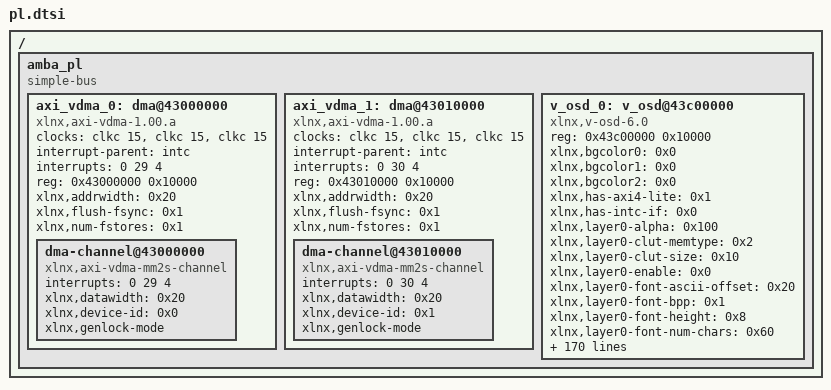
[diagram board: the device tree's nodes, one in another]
/*
 * CAUTION: This file is automatically generated by Xilinx.
 * Version: HSI 2016.3
 * Today is: Tue Nov 29 15:11:29 2016
*/


/ {
	amba_pl: amba_pl {
		#address-cells = <1>;
		#size-cells = <1>;
		compatible = "simple-bus";
		ranges ;
		axi_vdma_0: dma@43000000 {
			#dma-cells = <1>;
			clock-names = "s_axi_lite_aclk", "m_axi_mm2s_aclk", "m_axi_mm2s_aclk";
			clocks = <&clkc 15>, <&clkc 15>, <&clkc 15>;
			compatible = "xlnx,axi-vdma-1.00.a";
			interrupt-parent = <&intc>;
			interrupts = <0 29 4>;
			reg = <0x43000000 0x10000>;
			xlnx,addrwidth = <0x20>;
			xlnx,flush-fsync = <0x1>;
			xlnx,num-fstores = <0x1>;
			dma-channel@43000000 {
				compatible = "xlnx,axi-vdma-mm2s-channel";
				interrupts = <0 29 4>;
				xlnx,datawidth = <0x20>;
				xlnx,device-id = <0x0>;
				xlnx,genlock-mode ;
			};
		};
		axi_vdma_1: dma@43010000 {
			#dma-cells = <1>;
			clock-names = "s_axi_lite_aclk", "m_axi_mm2s_aclk", "m_axi_mm2s_aclk";
			clocks = <&clkc 15>, <&clkc 15>, <&clkc 15>;
			compatible = "xlnx,axi-vdma-1.00.a";
			interrupt-parent = <&intc>;
			interrupts = <0 30 4>;
			reg = <0x43010000 0x10000>;
			xlnx,addrwidth = <0x20>;
			xlnx,flush-fsync = <0x1>;
			xlnx,num-fstores = <0x1>;
			dma-channel@43010000 {
				compatible = "xlnx,axi-vdma-mm2s-channel";
				interrupts = <0 30 4>;
				xlnx,datawidth = <0x20>;
				xlnx,device-id = <0x1>;
				xlnx,genlock-mode ;
			};
		};
		v_osd_0: v_osd@43c00000 {
			compatible = "xlnx,v-osd-6.0";
			reg = <0x43c00000 0x10000>;
			xlnx,bgcolor0 = <0x0>;
			xlnx,bgcolor1 = <0x0>;
			xlnx,bgcolor2 = <0x0>;
			xlnx,has-axi4-lite = <0x1>;
			xlnx,has-intc-if = <0x0>;
			xlnx,layer0-alpha = <0x100>;
			xlnx,layer0-clut-memtype = <0x2>;
			xlnx,layer0-clut-size = <0x10>;
			xlnx,layer0-enable = <0x0>;
			xlnx,layer0-font-ascii-offset = <0x20>;
			xlnx,layer0-font-bpp = <0x1>;
			xlnx,layer0-font-height = <0x8>;
			xlnx,layer0-font-num-chars = <0x60>;
			xlnx,layer0-font-width = <0x8>;
			xlnx,layer0-galpha-en = <0x1>;
			xlnx,layer0-imem-size = <0x30>;
			xlnx,layer0-ins-box-en = <0x1>;
			xlnx,layer0-ins-line-en = <0x0>;
			xlnx,layer0-ins-text-en = <0x1>;
			xlnx,layer0-priority = <0x0>;
			xlnx,layer0-text-max-string-length = <0x20>;
			xlnx,layer0-text-num-strings = <0x8>;
			xlnx,layer0-type = <0x2>;
			xlnx,layer0-x-pos = <0x0>;
			xlnx,layer0-x-size = <0x140>;
			xlnx,layer0-y-pos = <0x0>;
			xlnx,layer0-y-size = <0xf0>;
			xlnx,layer1-alpha = <0x100>;
			xlnx,layer1-clut-memtype = <0x2>;
			xlnx,layer1-clut-size = <0x10>;
			xlnx,layer1-enable = <0x0>;
			xlnx,layer1-font-ascii-offset = <0x20>;
			xlnx,layer1-font-bpp = <0x1>;
			xlnx,layer1-font-height = <0x8>;
			xlnx,layer1-font-num-chars = <0x60>;
			xlnx,layer1-font-width = <0x8>;
			xlnx,layer1-galpha-en = <0x1>;
			xlnx,layer1-imem-size = <0x30>;
			xlnx,layer1-ins-box-en = <0x1>;
			xlnx,layer1-ins-line-en = <0x0>;
			xlnx,layer1-ins-text-en = <0x1>;
			xlnx,layer1-priority = <0x1>;
			xlnx,layer1-text-max-string-length = <0x20>;
			xlnx,layer1-text-num-strings = <0x8>;
			xlnx,layer1-type = <0x2>;
			xlnx,layer1-x-pos = <0x0>;
			xlnx,layer1-x-size = <0x140>;
			xlnx,layer1-y-pos = <0x0>;
			xlnx,layer1-y-size = <0xf0>;
			xlnx,layer2-alpha = <0x100>;
			xlnx,layer2-clut-memtype = <0x2>;
			xlnx,layer2-clut-size = <0x10>;
			xlnx,layer2-enable = <0x0>;
			xlnx,layer2-font-ascii-offset = <0x20>;
			xlnx,layer2-font-bpp = <0x1>;
			xlnx,layer2-font-height = <0x8>;
			xlnx,layer2-font-num-chars = <0x60>;
			xlnx,layer2-font-width = <0x8>;
			xlnx,layer2-galpha-en = <0x1>;
			xlnx,layer2-imem-size = <0x30>;
			xlnx,layer2-ins-box-en = <0x1>;
			xlnx,layer2-ins-line-en = <0x0>;
			xlnx,layer2-ins-text-en = <0x1>;
			xlnx,layer2-priority = <0x2>;
			xlnx,layer2-text-max-string-length = <0x20>;
			xlnx,layer2-text-num-strings = <0x8>;
			xlnx,layer2-type = <0x2>;
			xlnx,layer2-x-pos = <0x0>;
			xlnx,layer2-x-size = <0x140>;
			xlnx,layer2-y-pos = <0x0>;
			xlnx,layer2-y-size = <0xf0>;
			xlnx,layer3-alpha = <0x100>;
			xlnx,layer3-clut-memtype = <0x2>;
			xlnx,layer3-clut-size = <0x10>;
			xlnx,layer3-enable = <0x0>;
			xlnx,layer3-font-ascii-offset = <0x20>;
			xlnx,layer3-font-bpp = <0x1>;
			xlnx,layer3-font-height = <0x8>;
			xlnx,layer3-font-num-chars = <0x60>;
			xlnx,layer3-font-width = <0x8>;
			xlnx,layer3-galpha-en = <0x1>;
			xlnx,layer3-imem-size = <0x30>;
			xlnx,layer3-ins-box-en = <0x1>;
			xlnx,layer3-ins-line-en = <0x0>;
			xlnx,layer3-ins-text-en = <0x1>;
			xlnx,layer3-priority = <0x3>;
			xlnx,layer3-text-max-string-length = <0x20>;
			xlnx,layer3-text-num-strings = <0x8>;
			xlnx,layer3-type = <0x2>;
			xlnx,layer3-x-pos = <0x0>;
			xlnx,layer3-x-size = <0x140>;
			xlnx,layer3-y-pos = <0x0>;
			xlnx,layer3-y-size = <0xf0>;
			xlnx,layer4-alpha = <0x100>;
			xlnx,layer4-clut-memtype = <0x2>;
			xlnx,layer4-clut-size = <0x10>;
			xlnx,layer4-enable = <0x0>;
			xlnx,layer4-font-ascii-offset = <0x20>;
			xlnx,layer4-font-bpp = <0x1>;
			xlnx,layer4-font-height = <0x8>;
			xlnx,layer4-font-num-chars = <0x60>;
			xlnx,layer4-font-width = <0x8>;
			xlnx,layer4-galpha-en = <0x0>;
			xlnx,layer4-imem-size = <0x30>;
			xlnx,layer4-ins-box-en = <0x1>;
			xlnx,layer4-ins-line-en = <0x0>;
			xlnx,layer4-ins-text-en = <0x1>;
			xlnx,layer4-priority = <0x3>;
			xlnx,layer4-text-max-string-length = <0x20>;
			xlnx,layer4-text-num-strings = <0x8>;
			xlnx,layer4-type = <0x0>;
			xlnx,layer4-x-pos = <0x0>;
			xlnx,layer4-x-size = <0x140>;
			xlnx,layer4-y-pos = <0x0>;
			xlnx,layer4-y-size = <0xf0>;
			xlnx,layer5-alpha = <0x100>;
			xlnx,layer5-clut-memtype = <0x2>;
			xlnx,layer5-clut-size = <0x10>;
			xlnx,layer5-enable = <0x0>;
			xlnx,layer5-font-ascii-offset = <0x20>;
			xlnx,layer5-font-bpp = <0x1>;
			xlnx,layer5-font-height = <0x8>;
			xlnx,layer5-font-num-chars = <0x60>;
			xlnx,layer5-font-width = <0x8>;
			xlnx,layer5-galpha-en = <0x0>;
			xlnx,layer5-imem-size = <0x30>;
			xlnx,layer5-ins-box-en = <0x1>;
			xlnx,layer5-ins-line-en = <0x0>;
			xlnx,layer5-ins-text-en = <0x1>;
			xlnx,layer5-priority = <0x3>;
			xlnx,layer5-text-max-string-length = <0x20>;
			xlnx,layer5-text-num-strings = <0x8>;
			xlnx,layer5-type = <0x0>;
			xlnx,layer5-x-pos = <0x0>;
			xlnx,layer5-x-size = <0x140>;
			xlnx,layer5-y-pos = <0x0>;
			xlnx,layer5-y-size = <0xf0>;
			xlnx,layer6-alpha = <0x100>;
			xlnx,layer6-clut-memtype = <0x2>;
			xlnx,layer6-clut-size = <0x10>;
			xlnx,layer6-enable = <0x0>;
			xlnx,layer6-font-ascii-offset = <0x20>;
			xlnx,layer6-font-bpp = <0x1>;
			xlnx,layer6-font-height = <0x8>;
			xlnx,layer6-font-num-chars = <0x60>;
			xlnx,layer6-font-width = <0x8>;
			xlnx,layer6-galpha-en = <0x0>;
			xlnx,layer6-imem-size = <0x30>;
			xlnx,layer6-ins-box-en = <0x1>;
			xlnx,layer6-ins-line-en = <0x0>;
			xlnx,layer6-ins-text-en = <0x1>;
			xlnx,layer6-priority = <0x3>;
			xlnx,layer6-text-max-string-length = <0x20>;
			xlnx,layer6-text-num-strings = <0x8>;
			xlnx,layer6-type = <0x0>;
			xlnx,layer6-x-pos = <0x0>;
			xlnx,layer6-x-size = <0x140>;
			xlnx,layer6-y-pos = <0x0>;
			xlnx,layer6-y-size = <0xf0>;
			xlnx,layer7-alpha = <0x100>;
			xlnx,layer7-clut-memtype = <0x2>;
			xlnx,layer7-clut-size = <0x10>;
			xlnx,layer7-enable = <0x0>;
			xlnx,layer7-font-ascii-offset = <0x20>;
			xlnx,layer7-font-bpp = <0x1>;
			xlnx,layer7-font-height = <0x8>;
			xlnx,layer7-font-num-chars = <0x60>;
			xlnx,layer7-font-width = <0x8>;
			xlnx,layer7-galpha-en = <0x0>;
			xlnx,layer7-imem-size = <0x30>;
			xlnx,layer7-ins-box-en = <0x1>;
			xlnx,layer7-ins-line-en = <0x0>;
			xlnx,layer7-ins-text-en = <0x1>;
			xlnx,layer7-priority = <0x3>;
			xlnx,layer7-text-max-string-length = <0x20>;
			xlnx,layer7-text-num-strings = <0x8>;
			xlnx,layer7-type = <0x0>;
			xlnx,layer7-x-pos = <0x0>;
			xlnx,layer7-x-size = <0x140>;
			xlnx,layer7-y-pos = <0x0>;
			xlnx,layer7-y-size = <0xf0>;
			xlnx,num-layers = <0x4>;
			xlnx,screen-width = <0x500>;
		};
	};
};
